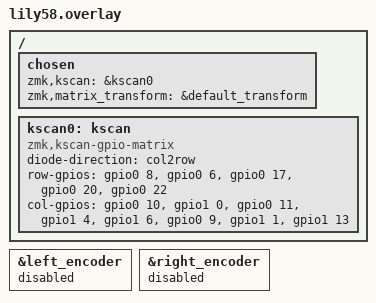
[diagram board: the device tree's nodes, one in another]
/ {
    chosen {
        zmk,kscan = &kscan0;
        zmk,matrix_transform = &default_transform;
    };

    /* This section tells ZMK it's a split keyboard */
    kscan0: kscan {
        compatible = "zmk,kscan-gpio-matrix";
        diode-direction = "col2row";

        row-gpios
            = <&gpio0 8  (GPIO_ACTIVE_HIGH | GPIO_PULL_DOWN)>
            , <&gpio0 6  (GPIO_ACTIVE_HIGH | GPIO_PULL_DOWN)>
            , <&gpio0 17 (GPIO_ACTIVE_HIGH | GPIO_PULL_DOWN)>
            , <&gpio0 20 (GPIO_ACTIVE_HIGH | GPIO_PULL_DOWN)>
            , <&gpio0 22 (GPIO_ACTIVE_HIGH | GPIO_PULL_DOWN)>
            ;

        col-gpios
            = <&gpio0 10 GPIO_ACTIVE_HIGH>
            , <&gpio1 0  GPIO_ACTIVE_HIGH>
            , <&gpio0 11 GPIO_ACTIVE_HIGH>
            , <&gpio1 4  GPIO_ACTIVE_HIGH>
            , <&gpio1 6  GPIO_ACTIVE_HIGH>
            , <&gpio0 9  GPIO_ACTIVE_HIGH>
            , <&gpio1 1  GPIO_ACTIVE_HIGH>
            , <&gpio1 13 GPIO_ACTIVE_HIGH>
            ;
    };
};

/* These settings ensure the left and right sides know who they are */
&left_encoder {
    status = "disabled";
};

&right_encoder {
    status = "disabled";
};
